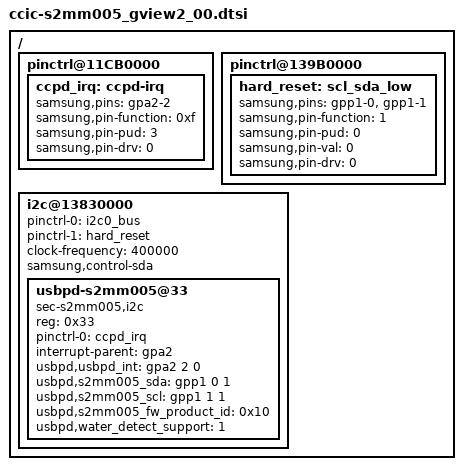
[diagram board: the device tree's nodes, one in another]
/*
 * SAMSUNG Hero Type C S2MM005 CCIC Device Tree Source
 *
 * Copyright (c) 2018 Samsung Electronics Co., Ltd.
 *		http://www.samsung.com
 *
 * This program is free software; you can redistribute it and/or modify
 * it under the terms of the GNU General Public License version 2 as
 * published by the Free Software Foundation.
*/

/ {
	pinctrl@11CB0000 {
		ccpd_irq: ccpd-irq {
			samsung,pins = "gpa2-2";
			samsung,pin-function = <0xf>;
			samsung,pin-pud = <3>;
			samsung,pin-drv = <0>;
		};
	};

	pinctrl@139B0000 {
		hard_reset: scl_sda_low {
			samsung,pins = "gpp1-0", "gpp1-1";
			samsung,pin-function = <1>;
			samsung,pin-pud = <0>;
			samsung,pin-val = <0>;
			samsung,pin-drv = <0>;
		};
	};

	i2c@13830000 {
		status = "okay";
		pinctrl-names = "default","hard_reset";
		pinctrl-0 = <&i2c0_bus>;
		pinctrl-1 = <&hard_reset>;
		clock-frequency = <400000>;
		samsung,control-sda;

		usbpd-s2mm005@33 {
			compatible = "sec-s2mm005,i2c";
			reg = <0x33>;
			pinctrl-names = "default";
			pinctrl-0 = <&ccpd_irq>;
			interrupt-parent = <&gpa2>;
			usbpd,usbpd_int = <&gpa2 2 0>;
			usbpd,s2mm005_sda = <&gpp1 0 1>;
			usbpd,s2mm005_scl = <&gpp1 1 1>;
			usbpd,s2mm005_fw_product_id = <0x10>;
			usbpd,water_detect_support = <1>;
		};
	};

/*
	usb@13600000 {
		dwc3 {
			maximum-speed = "high-speed";
		};
	};
*/
};

